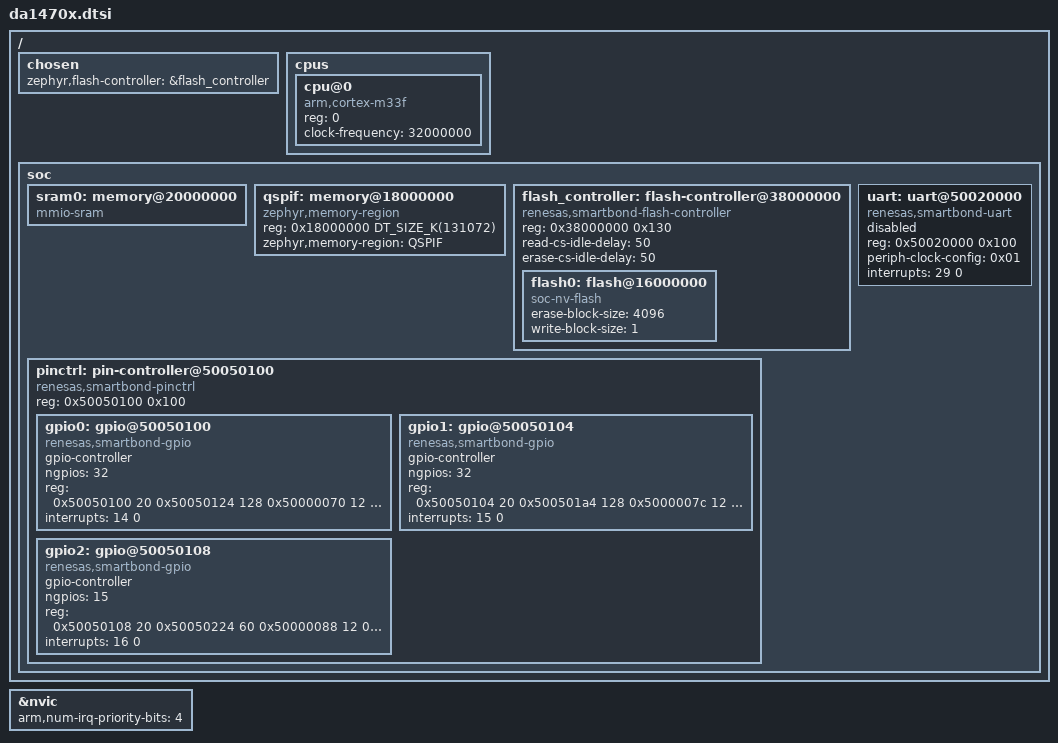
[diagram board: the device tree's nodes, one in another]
/*
 * Copyright (c) 2023 Renesas Electronics Corporation and/or its affiliates
 * SPDX-License-Identifier: Apache-2.0
 */

#include <arm/armv8-m.dtsi>
#include <mem.h>
#include <freq.h>
#include <zephyr/dt-bindings/gpio/gpio.h>
#include <zephyr/dt-bindings/adc/smartbond-adc.h>
#include <zephyr/dt-bindings/pinctrl/smartbond-pinctrl.h> //added

/ {
	chosen {
		//zephyr,entropy = &trng;
		zephyr,flash-controller = &flash_controller;
	};

	cpus: cpus {
		#address-cells = <1>;
		#size-cells = <0>;

		cpu@0 {
			compatible = "arm,cortex-m33f";
			reg = <0>;
			clock-frequency = <32000000>;
		};
	};

	// crg {
	// 	osc: osc {
	// 		// rc32k: rc32k {
	// 		// 	compatible = "renesas,smartbond-lp-osc";
	// 		// 	clock-frequency = <DT_FREQ_K(32)>;
	// 		// 	calibration-interval = <1>;
	// 		// 	#clock-cells = <0>;
	// 		// 	status = "okay";
	// 		// };
	// 		xtal32k: xtal32k {
	// 			compatible = "renesas,smartbond-lp-osc";
	// 			clock-frequency = <32768>;
	// 			settle-time = <8000>;
	// 			#clock-cells = <0>;
	// 			status = "disabled";
	// 		};
	// 		// rcx: rcx {
	// 		// 	compatible = "renesas,smartbond-lp-osc";
	// 		// 	clock-frequency = <DT_FREQ_K(15)>;
	// 		// 	calibration-interval = <1>;
	// 		// 	#clock-cells = <0>;
	// 		// 	status = "disabled";
	// 		// };
	// 		// rc32m: rc32m {
	// 		// 	compatible = "fixed-clock";
	// 		// 	clock-frequency = <DT_FREQ_M(32)>;
	// 		// 	#clock-cells = <0>;
	// 		// 	status = "okay";
	// 		// };
	// 		xtal32m: xtal32m {
	// 			compatible = "fixed-clock";
	// 			clock-frequency = <DT_FREQ_M(32)>;
	// 			#clock-cells = <0>;
	// 			status = "disabled";
	// 		};
	// 		// pll: pll {
	// 		// 	compatible = "fixed-clock";
	// 		// 	clock-frequency = <DT_FREQ_M(96)>;
	// 		// 	#clock-cells = <0>;
	// 		// 	status = "disabled";
	// 		// };
	// 	};
	// 	divn_clk: divn_clk {
	// 		compatible = "fixed-clock";
	// 		clock-frequency = <DT_FREQ_M(32)>;
	// 		#clock-cells = <0>;
	// 		status = "okay";
	// 	};
	// 	sys_clk: sys_clk {
	// 		compatible = "renesas,smartbond-sys-clk";
	// 		status = "okay";
	// 		clock-src = <&xtal32m>;
	// 		status = "okay";
	// 	};
	// 	lp_clk: lp_clk {
	// 		compatible = "renesas,smartbond-lp-clk";
	// 		clock-src = <&xtal32k>;
	// 		status = "okay";
	// 	};
	// };

	soc {
		sram0: memory@20000000 {
			compatible = "mmio-sram";
		};

		qspif: memory@18000000{
			compatible = "zephyr,memory-region";
			reg = <0x18000000 DT_SIZE_K(131072)>; //check if ok
			zephyr,memory-region = "QSPIF";
		};

		flash_controller: flash-controller@38000000 {
			compatible = "renesas,smartbond-flash-controller";
			reg = <0x38000000 0x130>;

			#address-cells = <1>;
			#size-cells = <1>;

			read-cs-idle-delay = <50>;
			erase-cs-idle-delay = <50>;

			flash0: flash@16000000 {
				compatible = "soc-nv-flash";
				erase-block-size = <4096>; //unknown
				write-block-size = <1>;
			};
		};


		pinctrl: pin-controller@50050100 {
			compatible = "renesas,smartbond-pinctrl";
			reg = <0x50050100 0x100>;
			#address-cells = <1>;
			#size-cells = <1>;

			gpio0: gpio@50050100 {
				compatible = "renesas,smartbond-gpio";
				gpio-controller;
				#gpio-cells = <2>;
				ngpios = <32>;
				reg = <0x50050100 20
					   0x50050124 128
					   0x50000070 12
					   0x50000908 36>;
				reg-names = "data", "mode", "latch", "wkup";
				interrupts = <14 0>;
			};

			gpio1: gpio@50050104 {
				compatible = "renesas,smartbond-gpio";
				gpio-controller;
				#gpio-cells = <2>;
				ngpios = <32>;
				reg = <0x50050104 20
					   0x500501a4 128
					   0x5000007c 12
					   0x5000090c 36>;
				reg-names = "data", "mode", "latch", "wkup";
				interrupts = <15 0>;
			};

			gpio2: gpio@50050108 {
				compatible = "renesas,smartbond-gpio";
				gpio-controller;
				#gpio-cells = <2>;
				ngpios = <15>;
				reg = <0x50050108 20
					   0x50050224 60
					   0x50000088 12
					   0x50000910 36>;
				reg-names = "data", "mode", "latch", "wkup";
				interrupts = <16 0>;
			};
		};

		uart: uart@50020000 {
			compatible = "renesas,smartbond-uart";
			reg = <0x50020000 0x100>;
			periph-clock-config = <0x01>;
			interrupts = <29 0>;
			status = "disabled";
		};

		// i2c: i2c@50020600 {
		// 	compatible = "renesas,smartbond-i2c";
		// 	#address-cells = <1>;
		// 	#size-cells = <0>;
		// 	reg = <0x50020600 0x100>;
		// 	periph-clock-config = <0x0200>;
		// 	interrupts = <35 0>;
		// 	status = "disabled";
		// };

		// i2c2: i2c@50020700 {
		// 	compatible = "renesas,smartbond-i2c";
		// 	#address-cells = <1>;
		// 	#size-cells = <0>;
		// 	reg = <0x50020700 0x100>;
		// 	periph-clock-config = <0x0800>;
		// 	interrupts = <36 0>;
		// };

		// i2c3: i2c@50020500 {
		// 	compatible = "renesas,smartbond-i2c";
		// 	#address-cells = <1>;
		// 	#size-cells = <0>;
		// 	reg = <0x50020500 0x100>;
		// 	periph-clock-config = <0x0800>;
		// 	interrupts = <37 0>;
		// };

		// spi: spi@50020300 {
		// 	compatible = "renesas,smartbond-spi";
		// 	#address-cells = <1>;
		// 	#size-cells = <0>;
		// 	reg = <0x50020300 0x100>;
		// 	periph-clock-config = <0x20>;
		// 	interrupts = <32 0>;
		// 	status = "disabled";
		// };

		// spi2: spi@50020400 {
		// 	compatible = "renesas,smartbond-spi";
		// 	#address-cells = <1>;
		// 	#size-cells = <0>;
		// 	reg = <0x50020400 0x100>;
		// 	periph-clock-config = <0x80>;
		// 	interrupts = <33 0>;
		// 	status = "disabled";
		// };

		// spi3: spi@50020200 {
		// 	compatible = "renesas,smartbond-spi";
		// 	#address-cells = <1>;
		// 	#size-cells = <0>;
		// 	reg = <0x50020200 0x100>;
		// 	periph-clock-config = <0x80>;
		// 	interrupts = <34 0>;
		// 	status = "disabled";
		// };
	};
};

&nvic {
	arm,num-irq-priority-bits = <4>;
};
